# PIC32MX450F128H register map
Vendor: Microchip
Registers are 32-bit, read-write, reset 0x0 unless marked. A register's access mark holds for its fields unless they carry their own. Addresses are absolute, and some are shared; only a register's first bit layout is shown; [hi:lo] are bit positions; {n}, {i} and the like mark numbered series; 'fields as' and 'values as' point back to an identical list.

## PORTF
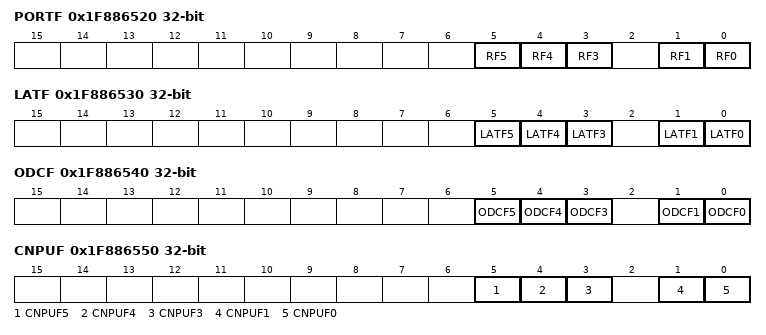
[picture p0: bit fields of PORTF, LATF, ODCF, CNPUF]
0x1F886520 PORTF reset not defined — (power-on value --------------------------xxx-xx)
  [5] RF5, [4] RF4, [3] RF3, [1] RF1, [0] RF0
0x1F886530 LATF reset not defined — (power-on value --------------------------xxx-xx)
  [5] LATF5, [4] LATF4, [3] LATF3, [1] LATF1, [0] LATF0
0x1F886540 ODCF
  [5] ODCF5, [4] ODCF4, [3] ODCF3, [1] ODCF1, [0] ODCF0
0x1F886550 CNPUF reset not defined — (power-on value --------------------------xxx-xx)
  [5] CNPUF5, [4] CNPUF4, [3] CNPUF3, [1] CNPUF1, [0] CNPUF0
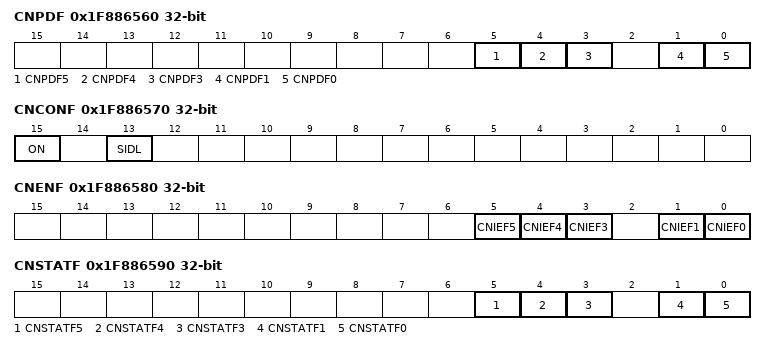
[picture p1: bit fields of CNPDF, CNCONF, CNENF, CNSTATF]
0x1F886560 CNPDF reset not defined — (power-on value --------------------------xxx-xx)
  [5] CNPDF5, [4] CNPDF4, [3] CNPDF3, [1] CNPDF1, [0] CNPDF0
0x1F886570 CNCONF
  [15] ON, [13] SIDL
0x1F886580 CNENF reset not defined — (power-on value 0000000000----------------xxx-xx)
  [5] CNIEF5, [4] CNIEF4, [3] CNIEF3, [1] CNIEF1, [0] CNIEF0
0x1F886590 CNSTATF reset not defined — (power-on value --------------------------xxx-xx)
  [5] CNSTATF5, [4] CNSTATF4, [3] CNSTATF3, [1] CNSTATF1, [0] CNSTATF0

## PORTG
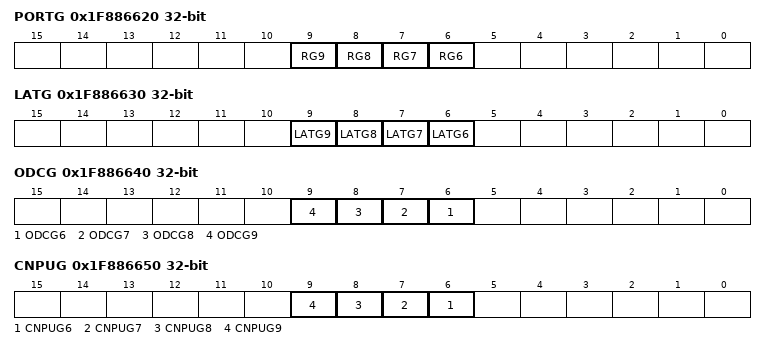
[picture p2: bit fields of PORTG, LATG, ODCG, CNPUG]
0x1F886620 PORTG reset not defined — (power-on value ----------------------xxxx------)
  [n] RG{n} (n=6..9)
0x1F886630 LATG reset not defined — (power-on value ----------------------xxxx------)
  [n] LATG{n} (n=6..9)
0x1F886640 ODCG
  [n] ODCG{n} (n=6..9)
0x1F886650 CNPUG reset not defined — (power-on value ----------------------xxxx------)
  [n] CNPUG{n} (n=6..9)
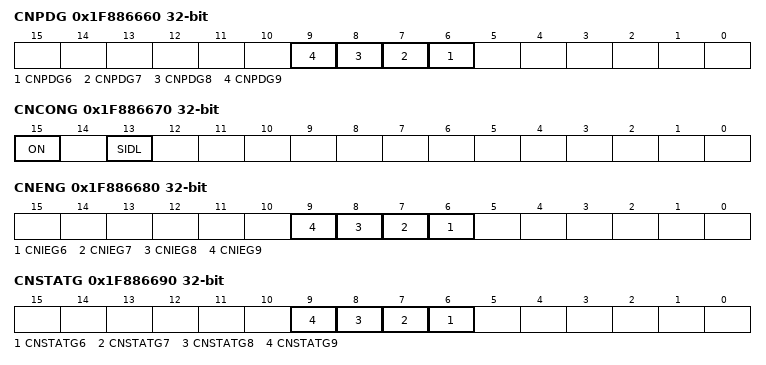
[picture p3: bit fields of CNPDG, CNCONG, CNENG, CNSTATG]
0x1F886660 CNPDG reset not defined — (power-on value ----------------------xxxx------)
  [n] CNPDG{n} (n=6..9)
0x1F886670 CNCONG
  [15] ON, [13] SIDL
0x1F886680 CNENG reset not defined — (power-on value 0000000000------------xxxx------)
  [n] CNIEG{n} (n=6..9)
0x1F886690 CNSTATG reset not defined — (power-on value ----------------------xxxx------)
  [n] CNSTATG{n} (n=6..9)

## WDT
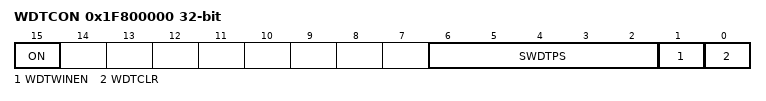
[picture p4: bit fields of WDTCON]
0x1F800000 WDTCON reset not defined — (power-on value ----------------0--------00000x0)
  [15] ON, [6:2] SWDTPS ro, [1] WDTWINEN, [0] WDTCLR

## RTCC
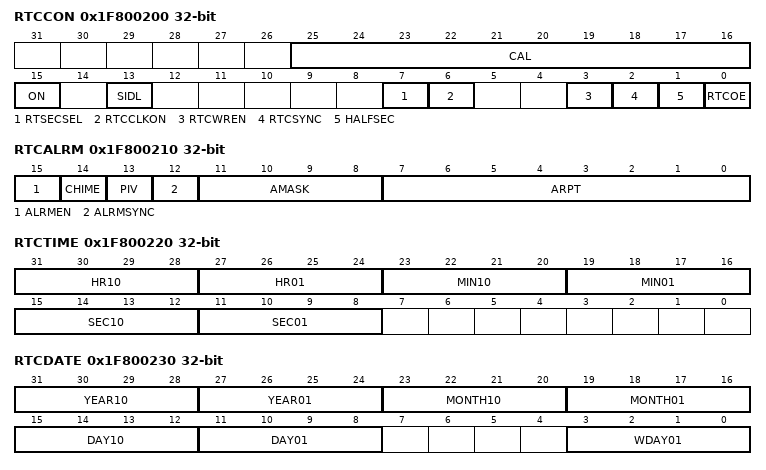
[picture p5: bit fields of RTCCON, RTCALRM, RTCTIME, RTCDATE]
0x1F800200 RTCCON
  [25:16] CAL, [15] ON, [13] SIDL, [7] RTSECSEL, [6] RTCCLKON, [3] RTCWREN, [2] RTCSYNC ro, [1] HALFSEC ro, [0] RTCOE
0x1F800210 RTCALRM
  [15] ALRMEN, [14] CHIME, [13] PIV, [12] ALRMSYNC, [11:8] AMASK, [7:0] ARPT
0x1F800220 RTCTIME reset not defined — (power-on value 000xxxxxxxxxxxxx0xxxxxxx--------)
  [31:28] HR10, [27:24] HR01, [23:20] MIN10, [19:16] MIN01, [15:12] SEC10, [11:8] SEC01
0x1F800230 RTCDATE reset not defined — (power-on value xxxxxxxx000xxxxx00xxxxxx----0xxx)
  [31:28] YEAR10, [27:24] YEAR01, [23:20] MONTH10, [19:16] MONTH01, [15:12] DAY10, [11:8] DAY01, [3:0] WDAY01
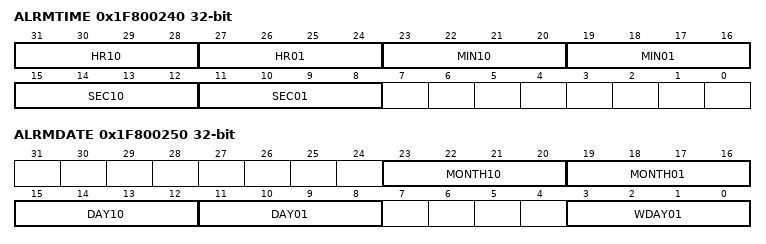
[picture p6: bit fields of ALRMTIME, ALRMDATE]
0x1F800240 ALRMTIME reset not defined — (power-on value 000xxxxx0xxxxxxx0xxxxxxx--------)
  fields as RTCTIME
0x1F800250 ALRMDATE reset not defined — (power-on value --------000xxxxx00xxxxxx----0xxx)
  [23:20] MONTH10, [19:16] MONTH01, [15:12] DAY10, [11:8] DAY01, [3:0] WDAY01

## TMR1
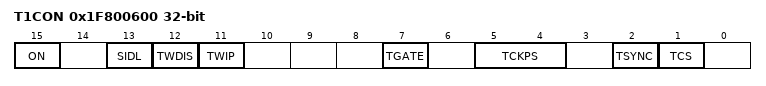
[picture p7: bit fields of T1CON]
0x1F800600 T1CON
  [15] ON, [13] SIDL, [12] TWDIS, [11] TWIP ro, [7] TGATE, [5:4] TCKPS, [2] TSYNC, [1] TCS
0x1F800610 TMR1
0x1F800620 PR1 reset 0xFFFF

## TMR2
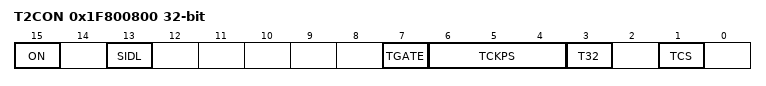
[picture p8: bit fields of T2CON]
0x1F800800 T2CON
  [15] ON, [13] SIDL, [7] TGATE, [6:4] TCKPS, [3] T32, [1] TCS
0x1F800810 TMR2
0x1F800820 PR2 reset 0xFFFF

## TMR3
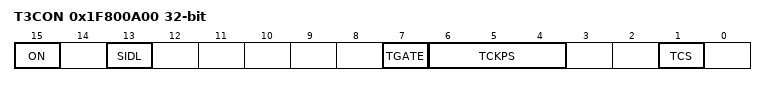
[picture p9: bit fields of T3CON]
0x1F800A00 T3CON
  [15] ON, [13] SIDL, [7] TGATE, [6:4] TCKPS, [1] TCS
0x1F800A10 TMR3
0x1F800A20 PR3 reset 0xFFFF

## TMR4
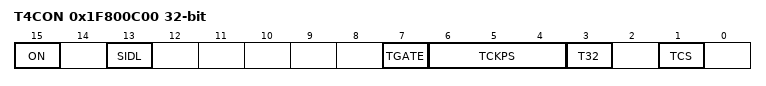
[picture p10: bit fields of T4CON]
0x1F800C00 T4CON
  [15] ON, [13] SIDL, [7] TGATE, [6:4] TCKPS, [3] T32, [1] TCS
0x1F800C10 TMR4
0x1F800C20 PR4 reset 0xFFFF

## TMR5
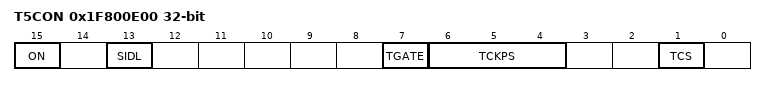
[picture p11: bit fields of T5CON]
0x1F800E00 T5CON
  [15] ON, [13] SIDL, [7] TGATE, [6:4] TCKPS, [1] TCS
0x1F800E10 TMR5
0x1F800E20 PR5 reset 0xFFFF
